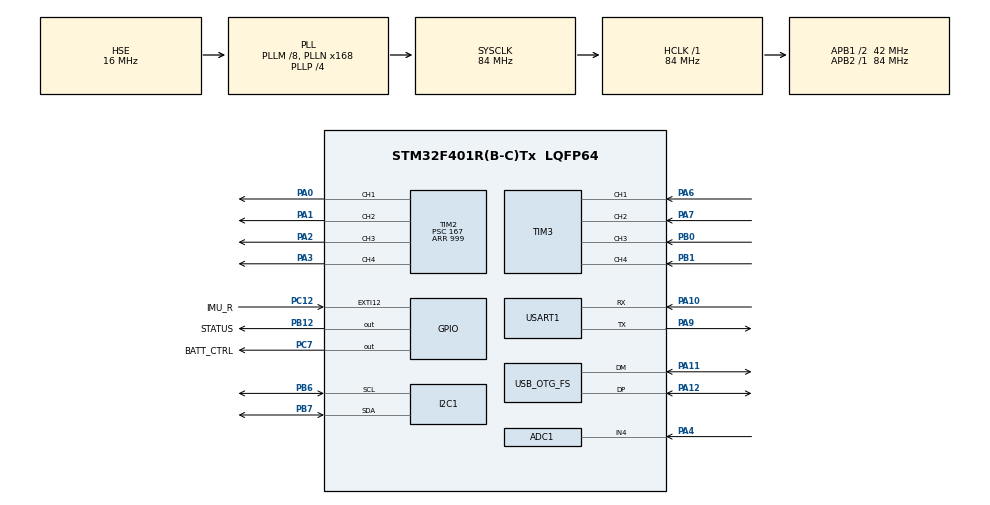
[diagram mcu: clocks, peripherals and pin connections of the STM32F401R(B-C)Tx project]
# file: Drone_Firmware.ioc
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ADC1.Channel-4\#ChannelRegularConversion=ADC_CHANNEL_4
ADC1.NbrOfConversionFlag=1
ADC1.Rank-4\#ChannelRegularConversion=1
ADC1.SamplingTime-4\#ChannelRegularConversion=ADC_SAMPLETIME_3CYCLES
ADC1.master=1
Dma.Request0=TIM3_CH1/TRIG
Dma.Request1=TIM3_CH2
Dma.Request2=TIM3_CH3
Dma.Request3=TIM3_CH4/UP
Dma.TIM3_CH1/TRIG.0.Direction=DMA_PERIPH_TO_MEMORY
Dma.TIM3_CH1/TRIG.0.FIFOMode=DMA_FIFOMODE_DISABLE
Dma.TIM3_CH1/TRIG.0.Instance=DMA1_Stream4
Dma.TIM3_CH1/TRIG.0.MemDataAlignment=DMA_MDATAALIGN_HALFWORD
Dma.TIM3_CH1/TRIG.0.MemInc=DMA_MINC_ENABLE
Dma.TIM3_CH1/TRIG.0.Mode=DMA_CIRCULAR
Dma.TIM3_CH1/TRIG.0.PeriphDataAlignment=DMA_PDATAALIGN_HALFWORD
Dma.TIM3_CH1/TRIG.0.PeriphInc=DMA_PINC_DISABLE
Dma.TIM3_CH1/TRIG.0.Priority=DMA_PRIORITY_LOW
Dma.TIM3_CH2.1.Direction=DMA_PERIPH_TO_MEMORY
Dma.TIM3_CH2.1.FIFOMode=DMA_FIFOMODE_DISABLE
Dma.TIM3_CH2.1.Instance=DMA1_Stream5
Dma.TIM3_CH2.1.MemDataAlignment=DMA_MDATAALIGN_HALFWORD
Dma.TIM3_CH2.1.MemInc=DMA_MINC_ENABLE
Dma.TIM3_CH2.1.Mode=DMA_CIRCULAR
Dma.TIM3_CH2.1.PeriphDataAlignment=DMA_PDATAALIGN_HALFWORD
Dma.TIM3_CH2.1.PeriphInc=DMA_PINC_DISABLE
Dma.TIM3_CH2.1.Priority=DMA_PRIORITY_LOW
Dma.TIM3_CH3.2.Direction=DMA_PERIPH_TO_MEMORY
Dma.TIM3_CH3.2.FIFOMode=DMA_FIFOMODE_DISABLE
Dma.TIM3_CH3.2.Instance=DMA1_Stream7
Dma.TIM3_CH3.2.MemDataAlignment=DMA_MDATAALIGN_HALFWORD
Dma.TIM3_CH3.2.MemInc=DMA_MINC_ENABLE
Dma.TIM3_CH3.2.Mode=DMA_CIRCULAR
Dma.TIM3_CH3.2.PeriphDataAlignment=DMA_PDATAALIGN_HALFWORD
Dma.TIM3_CH3.2.PeriphInc=DMA_PINC_DISABLE
Dma.TIM3_CH3.2.Priority=DMA_PRIORITY_LOW
Dma.TIM3_CH4/UP.3.Direction=DMA_PERIPH_TO_MEMORY
Dma.TIM3_CH4/UP.3.FIFOMode=DMA_FIFOMODE_DISABLE
Dma.TIM3_CH4/UP.3.Instance=DMA1_Stream2
Dma.TIM3_CH4/UP.3.MemDataAlignment=DMA_MDATAALIGN_HALFWORD
Dma.TIM3_CH4/UP.3.MemInc=DMA_MINC_ENABLE
Dma.TIM3_CH4/UP.3.Mode=DMA_CIRCULAR
Dma.TIM3_CH4/UP.3.PeriphDataAlignment=DMA_PDATAALIGN_HALFWORD
Dma.TIM3_CH4/UP.3.PeriphInc=DMA_PINC_DISABLE
Dma.TIM3_CH4/UP.3.Priority=DMA_PRIORITY_LOW
Mcu.Family=STM32F4
Mcu.Name=STM32F401R(B-C)Tx
Mcu.Package=LQFP64
NVIC.DMA1_Stream2_IRQn=true\:0\:0\:false\:false\:true\:false\:true\:true
NVIC.DMA1_Stream4_IRQn=true\:0\:0\:false\:false\:true\:false\:true\:true
NVIC.DMA1_Stream5_IRQn=true\:0\:0\:false\:false\:true\:false\:true\:true
NVIC.DMA1_Stream7_IRQn=true\:0\:0\:false\:false\:true\:false\:true\:true
NVIC.EXTI15_10_IRQn=true\:0\:0\:false\:false\:true\:true\:true\:true
NVIC.OTG_FS_IRQn=true\:0\:0\:false\:false\:true\:false\:true\:true
NVIC.PriorityGroup=NVIC_PRIORITYGROUP_4
PA0-WKUP.Signal=S_TIM2_CH1_ETR
PA1.Signal=S_TIM2_CH2
PA10.Mode=Asynchronous
PA10.Signal=USART1_RX
PA11.Mode=Device_Only
PA11.Signal=USB_OTG_FS_DM
PA12.Mode=Device_Only
PA12.Signal=USB_OTG_FS_DP
PA13.Mode=Serial_Wire
PA13.Signal=SYS_JTMS-SWDIO
PA14.Mode=Serial_Wire
PA14.Signal=SYS_JTCK-SWCLK
PA2.Signal=S_TIM2_CH3
PA3.Signal=S_TIM2_CH4
PA4.Signal=ADCx_IN4
PA6.Signal=S_TIM3_CH1
PA7.Signal=S_TIM3_CH2
PA9.Mode=Asynchronous
PA9.Signal=USART1_TX
PB0.Signal=S_TIM3_CH3
PB1.Signal=S_TIM3_CH4
PB12.GPIO_Label=STATUS
PB12.Signal=GPIO_Output
PB6.Mode=I2C
PB6.Signal=I2C1_SCL
PB7.Mode=I2C
PB7.Signal=I2C1_SDA
PC12.GPIO_Label=IMU_R
PC12.GPIO_ModeDefaultEXTI=GPIO_MODE_IT_RISING
PC12.Signal=GPXTI12
PC7.GPIO_Label=BATT_CTRL
PC7.Signal=GPIO_Output
PH0\ -\ OSC_IN.Mode=HSE-External-Oscillator
PH0\ -\ OSC_IN.Signal=RCC_OSC_IN
PH1\ -\ OSC_OUT.Mode=HSE-External-Oscillator
PH1\ -\ OSC_OUT.Signal=RCC_OSC_OUT
ProjectManager.HeapSize=0x200
ProjectManager.StackSize=0x400
ProjectManager.TargetToolchain=STM32CubeIDE
RCC.48MHZClocksFreq_Value=48000000
RCC.AHBFreq_Value=84000000
RCC.APB1CLKDivider=RCC_HCLK_DIV2
RCC.APB1Freq_Value=42000000
RCC.APB1TimFreq_Value=84000000
RCC.APB2Freq_Value=84000000
RCC.APB2TimFreq_Value=84000000
RCC.CortexFreq_Value=84000000
RCC.HCLKFreq_Value=84000000
RCC.HSE_VALUE=16000000
RCC.HSI_VALUE=16000000
RCC.LSE_VALUE=32768
RCC.PLLM=8
RCC.PLLN=168
RCC.PLLP=RCC_PLLP_DIV4
RCC.PLLQ=7
RCC.SYSCLKFreq_VALUE=84000000
RCC.SYSCLKSource=RCC_SYSCLKSOURCE_PLLCLK
RCC.VCOOutputFreq_Value=336000000
SH.ADCx_IN4.0=ADC1_IN4,IN4
SH.S_TIM2_CH1_ETR.0=TIM2_CH1,PWM Generation1 CH1
SH.S_TIM2_CH2.0=TIM2_CH2,PWM Generation2 CH2
SH.S_TIM2_CH3.0=TIM2_CH3,PWM Generation3 CH3
SH.S_TIM2_CH4.0=TIM2_CH4,PWM Generation4 CH4
SH.S_TIM3_CH1.0=TIM3_CH1,Input_Capture1_from_TI1
SH.S_TIM3_CH2.0=TIM3_CH2,Input_Capture2_from_TI2
SH.S_TIM3_CH3.0=TIM3_CH3,Input_Capture3_from_TI3
SH.S_TIM3_CH4.0=TIM3_CH4,Input_Capture4_from_TI4
TIM2.Channel-PWM\ Generation1\ CH1=TIM_CHANNEL_1
TIM2.Channel-PWM\ Generation2\ CH2=TIM_CHANNEL_2
TIM2.Channel-PWM\ Generation3\ CH3=TIM_CHANNEL_3
TIM2.Channel-PWM\ Generation4\ CH4=TIM_CHANNEL_4
TIM2.Period=999
TIM2.Prescaler=167
TIM3.Channel-Input_Capture1_from_TI1=TIM_CHANNEL_1
TIM3.Channel-Input_Capture2_from_TI2=TIM_CHANNEL_2
TIM3.Channel-Input_Capture3_from_TI3=TIM_CHANNEL_3
TIM3.Channel-Input_Capture4_from_TI4=TIM_CHANNEL_4
USART1.VirtualMode=VM_ASYNC
USB_DEVICE.CLASS_NAME_FS=CDC
USB_DEVICE.VirtualMode=Cdc
USB_DEVICE.VirtualModeFS=Cdc_FS
USB_OTG_FS.VirtualMode=Device_Only
VP_TIM2_VS_ClockSourceINT.Mode=Internal
VP_USB_DEVICE_VS_USB_DEVICE_CDC_FS.Mode=CDC_FS
board=custom

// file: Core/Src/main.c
/* USER CODE BEGIN Header */
/**
  ******************************************************************************
  * @file           : main.c
  * @brief          : Main program body
  ******************************************************************************
  * @attention
  *
  * Copyright (c) 2025 STMicroelectronics.
  * All rights reserved.
  *
  * This software is licensed under terms that can be found in the LICENSE file
  * in the root directory of this software component.
  * If no LICENSE file comes with this software, it is provided AS-IS.
  *
  ******************************************************************************
  */
/* USER CODE END Header */
#include "main.h"
#include "usb_device.h"

#include "Application/application.hpp"

ADC_HandleTypeDef hadc1;

I2C_HandleTypeDef hi2c1;

TIM_HandleTypeDef htim2;
TIM_HandleTypeDef htim3;
DMA_HandleTypeDef hdma_tim3_ch1_trig;
DMA_HandleTypeDef hdma_tim3_ch2;
DMA_HandleTypeDef hdma_tim3_ch3;
DMA_HandleTypeDef hdma_tim3_ch4_up;

UART_HandleTypeDef huart1;

void SystemClock_Config(void);
static void MX_GPIO_Init(void);
static void MX_DMA_Init(void);
static void MX_ADC1_Init(void);
static void MX_I2C1_Init(void);
static void MX_TIM2_Init(void);
static void MX_TIM3_Init(void);
static void MX_USART1_UART_Init(void);

void start (I2C_HandleTypeDef *n_i2c_handle, TIM_HandleTypeDef *htim2, TIM_HandleTypeDef *htim3, ADC_HandleTypeDef* adc_handle_p);

int main(void)
{

  /* MCU Configuration--------------------------------------------------------*/

  /* Reset of all peripherals, Initializes the Flash interface and the Systick. */
  HAL_Init();

  /* Configure the system clock */
  SystemClock_Config();

  /* Initialize all configured peripherals */
  MX_GPIO_Init();
  MX_DMA_Init();
  MX_ADC1_Init();
  MX_I2C1_Init();
  MX_TIM2_Init();
  MX_TIM3_Init();
  MX_USART1_UART_Init();
  MX_USB_DEVICE_Init();
  /* USER CODE BEGIN 2 */

  start (&hi2c1, &htim2, &htim3, &hadc1);

  /* USER CODE END 2 */

  /* Infinite loop */
  while (1)
  {

  }
}

void SystemClock_Config(void)
{
  RCC_OscInitTypeDef RCC_OscInitStruct = {0};
  RCC_ClkInitTypeDef RCC_ClkInitStruct = {0};

  /** Configure the main internal regulator output voltage
  */
  __HAL_RCC_PWR_CLK_ENABLE();
  __HAL_PWR_VOLTAGESCALING_CONFIG(PWR_REGULATOR_VOLTAGE_SCALE2);

  /** Initializes the RCC Oscillators according to the specified parameters
  * in the RCC_OscInitTypeDef structure.
  */
  RCC_OscInitStruct.OscillatorType = RCC_OSCILLATORTYPE_HSE;
  RCC_OscInitStruct.HSEState = RCC_HSE_ON;
  RCC_OscInitStruct.PLL.PLLState = RCC_PLL_ON;
  RCC_OscInitStruct.PLL.PLLSource = RCC_PLLSOURCE_HSE;
  RCC_OscInitStruct.PLL.PLLM = 8;
  RCC_OscInitStruct.PLL.PLLN = 168;
  RCC_OscInitStruct.PLL.PLLP = RCC_PLLP_DIV4;
  RCC_OscInitStruct.PLL.PLLQ = 7;
  if (HAL_RCC_OscConfig(&RCC_OscInitStruct) != HAL_OK)
  {
    Error_Handler();
  }

  /** Initializes the CPU, AHB and APB buses clocks
  */
  RCC_ClkInitStruct.ClockType = RCC_CLOCKTYPE_HCLK|RCC_CLOCKTYPE_SYSCLK
                              |RCC_CLOCKTYPE_PCLK1|RCC_CLOCKTYPE_PCLK2;
  RCC_ClkInitStruct.SYSCLKSource = RCC_SYSCLKSOURCE_PLLCLK;
  RCC_ClkInitStruct.AHBCLKDivider = RCC_SYSCLK_DIV1;
  RCC_ClkInitStruct.APB1CLKDivider = RCC_HCLK_DIV2;
  RCC_ClkInitStruct.APB2CLKDivider = RCC_HCLK_DIV1;

  if (HAL_RCC_ClockConfig(&RCC_ClkInitStruct, FLASH_LATENCY_2) != HAL_OK)
  {
    Error_Handler();
  }
}

static void MX_ADC1_Init(void)
{

  ADC_ChannelConfTypeDef sConfig = {0};

  /** Configure the global features of the ADC (Clock, Resolution, Data Alignment and number of conversion)
  */
  hadc1.Instance = ADC1;
  hadc1.Init.ClockPrescaler = ADC_CLOCK_SYNC_PCLK_DIV4;
  hadc1.Init.Resolution = ADC_RESOLUTION_12B;
  hadc1.Init.ScanConvMode = DISABLE;
  hadc1.Init.ContinuousConvMode = DISABLE;
  hadc1.Init.DiscontinuousConvMode = DISABLE;
  hadc1.Init.ExternalTrigConvEdge = ADC_EXTERNALTRIGCONVEDGE_NONE;
  hadc1.Init.ExternalTrigConv = ADC_SOFTWARE_START;
  hadc1.Init.DataAlign = ADC_DATAALIGN_RIGHT;
  hadc1.Init.NbrOfConversion = 1;
  hadc1.Init.DMAContinuousRequests = DISABLE;
  hadc1.Init.EOCSelection = ADC_EOC_SINGLE_CONV;
  if (HAL_ADC_Init(&hadc1) != HAL_OK)
  {
    Error_Handler();
  }

  /** Configure for the selected ADC regular channel its corresponding rank in the sequencer and its sample time.
  */
  sConfig.Channel = ADC_CHANNEL_4;
  sConfig.Rank = 1;
  sConfig.SamplingTime = ADC_SAMPLETIME_3CYCLES;
  if (HAL_ADC_ConfigChannel(&hadc1, &sConfig) != HAL_OK)
  {
    Error_Handler();
  }

}

static void MX_I2C1_Init(void)
{

  hi2c1.Instance = I2C1;
  hi2c1.Init.ClockSpeed = 100000;
  hi2c1.Init.DutyCycle = I2C_DUTYCYCLE_2;
  hi2c1.Init.OwnAddress1 = 0;
  hi2c1.Init.AddressingMode = I2C_ADDRESSINGMODE_7BIT;
  hi2c1.Init.DualAddressMode = I2C_DUALADDRESS_DISABLE;
  hi2c1.Init.OwnAddress2 = 0;
  hi2c1.Init.GeneralCallMode = I2C_GENERALCALL_DISABLE;
  hi2c1.Init.NoStretchMode = I2C_NOSTRETCH_DISABLE;
  if (HAL_I2C_Init(&hi2c1) != HAL_OK)
  {
    Error_Handler();
  }

}

static void MX_TIM2_Init(void)
{

  TIM_ClockConfigTypeDef sClockSourceConfig = {0};
  TIM_MasterConfigTypeDef sMasterConfig = {0};
  TIM_OC_InitTypeDef sConfigOC = {0};

  htim2.Instance = TIM2;
  htim2.Init.Prescaler = 167;
  htim2.Init.CounterMode = TIM_COUNTERMODE_UP;
  htim2.Init.Period = 999;
  htim2.Init.ClockDivision = TIM_CLOCKDIVISION_DIV1;
  htim2.Init.AutoReloadPreload = TIM_AUTORELOAD_PRELOAD_DISABLE;
  if (HAL_TIM_Base_Init(&htim2) != HAL_OK)
  {
    Error_Handler();
  }
  sClockSourceConfig.ClockSource = TIM_CLOCKSOURCE_INTERNAL;
  if (HAL_TIM_ConfigClockSource(&htim2, &sClockSourceConfig) != HAL_OK)
  {
    Error_Handler();
  }
  if (HAL_TIM_PWM_Init(&htim2) != HAL_OK)
  {
    Error_Handler();
  }
  sMasterConfig.MasterOutputTrigger = TIM_TRGO_RESET;
  sMasterConfig.MasterSlaveMode = TIM_MASTERSLAVEMODE_DISABLE;
  if (HAL_TIMEx_MasterConfigSynchronization(&htim2, &sMasterConfig) != HAL_OK)
  {
    Error_Handler();
  }
  sConfigOC.OCMode = TIM_OCMODE_PWM1;
  sConfigOC.Pulse = 0;
  sConfigOC.OCPolarity = TIM_OCPOLARITY_HIGH;
  sConfigOC.OCFastMode = TIM_OCFAST_DISABLE;
  if (HAL_TIM_PWM_ConfigChannel(&htim2, &sConfigOC, TIM_CHANNEL_1) != HAL_OK)
  {
    Error_Handler();
  }
  if (HAL_TIM_PWM_ConfigChannel(&htim2, &sConfigOC, TIM_CHANNEL_2) != HAL_OK)
  {
    Error_Handler();
  }
  if (HAL_TIM_PWM_ConfigChannel(&htim2, &sConfigOC, TIM_CHANNEL_3) != HAL_OK)
  {
    Error_Handler();
  }
  if (HAL_TIM_PWM_ConfigChannel(&htim2, &sConfigOC, TIM_CHANNEL_4) != HAL_OK)
  {
    Error_Handler();
  }
  HAL_TIM_MspPostInit(&htim2);

}

static void MX_TIM3_Init(void)
{

  TIM_MasterConfigTypeDef sMasterConfig = {0};
  TIM_IC_InitTypeDef sConfigIC = {0};

  htim3.Instance = TIM3;
  htim3.Init.Prescaler = 0;
  htim3.Init.CounterMode = TIM_COUNTERMODE_UP;
  htim3.Init.Period = 65535;
  htim3.Init.ClockDivision = TIM_CLOCKDIVISION_DIV1;
  htim3.Init.AutoReloadPreload = TIM_AUTORELOAD_PRELOAD_DISABLE;
  if (HAL_TIM_IC_Init(&htim3) != HAL_OK)
  {
    Error_Handler();
  }
  sMasterConfig.MasterOutputTrigger = TIM_TRGO_RESET;
  sMasterConfig.MasterSlaveMode = TIM_MASTERSLAVEMODE_DISABLE;
  if (HAL_TIMEx_MasterConfigSynchronization(&htim3, &sMasterConfig) != HAL_OK)
  {
    Error_Handler();
  }
  sConfigIC.ICPolarity = TIM_INPUTCHANNELPOLARITY_RISING;
  sConfigIC.ICSelection = TIM_ICSELECTION_DIRECTTI;
  sConfigIC.ICPrescaler = TIM_ICPSC_DIV1;
  sConfigIC.ICFilter = 0;
  if (HAL_TIM_IC_ConfigChannel(&htim3, &sConfigIC, TIM_CHANNEL_1) != HAL_OK)
  {
    Error_Handler();
  }
  if (HAL_TIM_IC_ConfigChannel(&htim3, &sConfigIC, TIM_CHANNEL_2) != HAL_OK)
  {
    Error_Handler();
  }
  if (HAL_TIM_IC_ConfigChannel(&htim3, &sConfigIC, TIM_CHANNEL_3) != HAL_OK)
  {
    Error_Handler();
  }
  if (HAL_TIM_IC_ConfigChannel(&htim3, &sConfigIC, TIM_CHANNEL_4) != HAL_OK)
  {
    Error_Handler();
  }

}

static void MX_USART1_UART_Init(void)
{

  huart1.Instance = USART1;
  huart1.Init.BaudRate = 115200;
  huart1.Init.WordLength = UART_WORDLENGTH_8B;
  huart1.Init.StopBits = UART_STOPBITS_1;
  huart1.Init.Parity = UART_PARITY_NONE;
  huart1.Init.Mode = UART_MODE_TX_RX;
  huart1.Init.HwFlowCtl = UART_HWCONTROL_NONE;
  huart1.Init.OverSampling = UART_OVERSAMPLING_16;
  if (HAL_UART_Init(&huart1) != HAL_OK)
  {
    Error_Handler();
  }

}

static void MX_DMA_Init(void)
{

  /* DMA controller clock enable */
  __HAL_RCC_DMA1_CLK_ENABLE();

  /* DMA interrupt init */
  /* DMA1_Stream2_IRQn interrupt configuration */
  HAL_NVIC_SetPriority(DMA1_Stream2_IRQn, 0, 0);
  HAL_NVIC_EnableIRQ(DMA1_Stream2_IRQn);
  /* DMA1_Stream4_IRQn interrupt configuration */
  HAL_NVIC_SetPriority(DMA1_Stream4_IRQn, 0, 0);
  HAL_NVIC_EnableIRQ(DMA1_Stream4_IRQn);
  /* DMA1_Stream5_IRQn interrupt configuration */
  HAL_NVIC_SetPriority(DMA1_Stream5_IRQn, 0, 0);
  HAL_NVIC_EnableIRQ(DMA1_Stream5_IRQn);
  /* DMA1_Stream7_IRQn interrupt configuration */
  HAL_NVIC_SetPriority(DMA1_Stream7_IRQn, 0, 0);
  HAL_NVIC_EnableIRQ(DMA1_Stream7_IRQn);

}

static void MX_GPIO_Init(void)
{
  GPIO_InitTypeDef GPIO_InitStruct = {0};

  /* GPIO Ports Clock Enable */
  __HAL_RCC_GPIOH_CLK_ENABLE();
  __HAL_RCC_GPIOA_CLK_ENABLE();
  __HAL_RCC_GPIOB_CLK_ENABLE();
  __HAL_RCC_GPIOC_CLK_ENABLE();

  /*Configure GPIO pin Output Level */
  HAL_GPIO_WritePin(STATUS_GPIO_Port, STATUS_Pin, GPIO_PIN_RESET);

  /*Configure GPIO pin Output Level */
  HAL_GPIO_WritePin(BATT_CTRL_GPIO_Port, BATT_CTRL_Pin, GPIO_PIN_RESET);

  /*Configure GPIO pin : STATUS_Pin */
  GPIO_InitStruct.Pin = STATUS_Pin;
  GPIO_InitStruct.Mode = GPIO_MODE_OUTPUT_PP;
  GPIO_InitStruct.Pull = GPIO_NOPULL;
  GPIO_InitStruct.Speed = GPIO_SPEED_FREQ_LOW;
  HAL_GPIO_Init(STATUS_GPIO_Port, &GPIO_InitStruct);

  /*Configure GPIO pin : BATT_CTRL_Pin */
  GPIO_InitStruct.Pin = BATT_CTRL_Pin;
  GPIO_InitStruct.Mode = GPIO_MODE_OUTPUT_PP;
  GPIO_InitStruct.Pull = GPIO_NOPULL;
  GPIO_InitStruct.Speed = GPIO_SPEED_FREQ_LOW;
  HAL_GPIO_Init(BATT_CTRL_GPIO_Port, &GPIO_InitStruct);

  /*Configure GPIO pin : IMU_R_Pin */
  GPIO_InitStruct.Pin = IMU_R_Pin;
  GPIO_InitStruct.Mode = GPIO_MODE_IT_RISING;
  GPIO_InitStruct.Pull = GPIO_NOPULL;
  HAL_GPIO_Init(IMU_R_GPIO_Port, &GPIO_InitStruct);

  /* EXTI interrupt init*/
  HAL_NVIC_SetPriority(EXTI15_10_IRQn, 0, 0);
  HAL_NVIC_EnableIRQ(EXTI15_10_IRQn);

}

void Error_Handler(void)
{
  __disable_irq();
  while (1)
  {
  }
}
